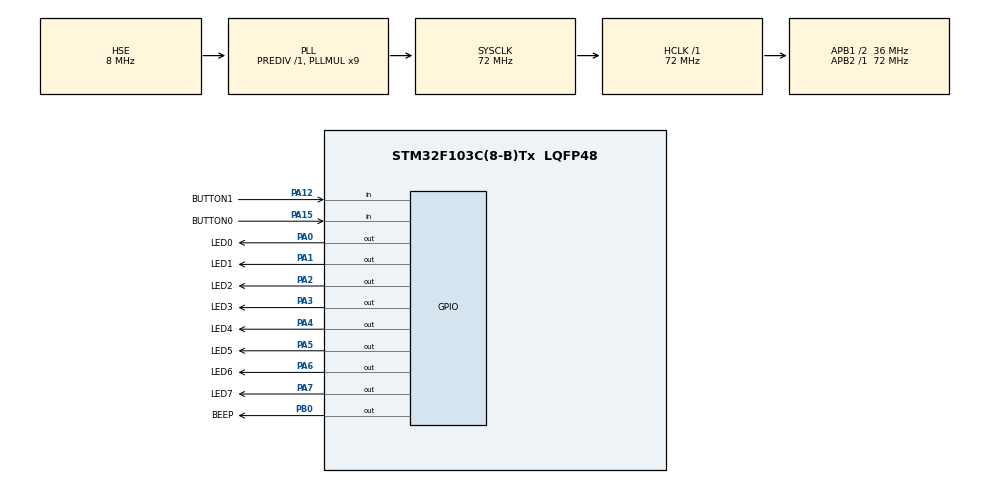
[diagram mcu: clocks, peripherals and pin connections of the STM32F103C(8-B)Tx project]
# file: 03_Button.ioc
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Mcu.Family=STM32F1
Mcu.Name=STM32F103C(8-B)Tx
Mcu.Package=LQFP48
NVIC.PriorityGroup=NVIC_PRIORITYGROUP_4
PA0-WKUP.GPIO_Label=LED0
PA0-WKUP.GPIO_ModeDefaultOutputPP=GPIO_MODE_OUTPUT_PP
PA0-WKUP.GPIO_PuPd=GPIO_PULLUP
PA0-WKUP.PinState=GPIO_PIN_SET
PA0-WKUP.Signal=GPIO_Output
PA1.GPIO_Label=LED1
PA1.GPIO_ModeDefaultOutputPP=GPIO_MODE_OUTPUT_PP
PA1.GPIO_PuPd=GPIO_PULLUP
PA1.GPIO_Speed=GPIO_SPEED_FREQ_LOW
PA1.PinState=GPIO_PIN_SET
PA1.Signal=GPIO_Output
PA12.GPIO_Label=BUTTON1
PA12.GPIO_PuPd=GPIO_PULLUP
PA12.Signal=GPIO_Input
PA13.Mode=Serial_Wire
PA13.Signal=SYS_JTMS-SWDIO
PA14.Mode=Serial_Wire
PA14.Signal=SYS_JTCK-SWCLK
PA15.GPIO_Label=BUTTON0
PA15.GPIO_PuPd=GPIO_PULLUP
PA15.Signal=GPIO_Input
PA2.GPIO_Label=LED2
PA2.GPIO_ModeDefaultOutputPP=GPIO_MODE_OUTPUT_PP
PA2.GPIO_PuPd=GPIO_PULLUP
PA2.GPIO_Speed=GPIO_SPEED_FREQ_LOW
PA2.PinState=GPIO_PIN_SET
PA2.Signal=GPIO_Output
PA3.GPIO_Label=LED3
PA3.GPIO_ModeDefaultOutputPP=GPIO_MODE_OUTPUT_PP
PA3.GPIO_PuPd=GPIO_PULLUP
PA3.GPIO_Speed=GPIO_SPEED_FREQ_LOW
PA3.PinState=GPIO_PIN_SET
PA3.Signal=GPIO_Output
PA4.GPIO_Label=LED4
PA4.GPIO_ModeDefaultOutputPP=GPIO_MODE_OUTPUT_PP
PA4.GPIO_PuPd=GPIO_PULLUP
PA4.GPIO_Speed=GPIO_SPEED_FREQ_LOW
PA4.PinState=GPIO_PIN_SET
PA4.Signal=GPIO_Output
PA5.GPIO_Label=LED5
PA5.GPIO_ModeDefaultOutputPP=GPIO_MODE_OUTPUT_PP
PA5.GPIO_PuPd=GPIO_PULLUP
PA5.GPIO_Speed=GPIO_SPEED_FREQ_LOW
PA5.PinState=GPIO_PIN_SET
PA5.Signal=GPIO_Output
PA6.GPIO_Label=LED6
PA6.GPIO_ModeDefaultOutputPP=GPIO_MODE_OUTPUT_PP
PA6.GPIO_PuPd=GPIO_PULLUP
PA6.GPIO_Speed=GPIO_SPEED_FREQ_LOW
PA6.PinState=GPIO_PIN_SET
PA6.Signal=GPIO_Output
PA7.GPIO_Label=LED7
PA7.GPIO_ModeDefaultOutputPP=GPIO_MODE_OUTPUT_PP
PA7.GPIO_PuPd=GPIO_PULLUP
PA7.GPIO_Speed=GPIO_SPEED_FREQ_LOW
PA7.PinState=GPIO_PIN_SET
PA7.Signal=GPIO_Output
PB0.GPIO_Label=BEEP
PB0.GPIO_PuPd=GPIO_PULLDOWN
PB0.Signal=GPIO_Output
PC14-OSC32_IN.Mode=LSE-External-Oscillator
PC14-OSC32_IN.Signal=RCC_OSC32_IN
PC15-OSC32_OUT.Mode=LSE-External-Oscillator
PC15-OSC32_OUT.Signal=RCC_OSC32_OUT
PD0-OSC_IN.Mode=HSE-External-Oscillator
PD0-OSC_IN.Signal=RCC_OSC_IN
PD1-OSC_OUT.Mode=HSE-External-Oscillator
PD1-OSC_OUT.Signal=RCC_OSC_OUT
ProjectManager.HeapSize=0x200
ProjectManager.StackSize=0x400
ProjectManager.TargetToolchain=STM32CubeIDE
RCC.AHBFreq_Value=72000000
RCC.APB1CLKDivider=RCC_HCLK_DIV2
RCC.APB1Freq_Value=36000000
RCC.APB1TimFreq_Value=72000000
RCC.APB2Freq_Value=72000000
RCC.APB2TimFreq_Value=72000000
RCC.HCLKFreq_Value=72000000
RCC.PLLMUL=RCC_PLL_MUL9
RCC.PLLSourceVirtual=RCC_PLLSOURCE_HSE
RCC.SYSCLKFreq_VALUE=72000000
RCC.SYSCLKSource=RCC_SYSCLKSOURCE_PLLCLK
RCC.USBFreq_Value=72000000
board=custom

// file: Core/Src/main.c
/* USER CODE BEGIN Header */
/**
  ******************************************************************************
  * @file           : main.c
  * @brief          : Main program body
  ******************************************************************************
  * @attention
  *
  * Copyright (c) 2025 STMicroelectronics.
  * All rights reserved.
  *
  * This software is licensed under terms that can be found in the LICENSE file
  * in the root directory of this software component.
  * If no LICENSE file comes with this software, it is provided AS-IS.
  *
  ******************************************************************************
  */
/* USER CODE END Header */
#include "main.h"
#include "gpio.h"

/* USER CODE BEGIN Includes */
#include "led.h"
#include "../../BSP/BEEP/beep.h"
#include "../../BSP/BUTTON/button.h"
/* USER CODE END Includes */

/* USER CODE BEGIN PD */
uint8_t button_down = 0;
/* USER CODE END PD */

void SystemClock_Config(void);

int main(void)
{

  /* MCU Configuration--------------------------------------------------------*/

  /* Reset of all peripherals, Initializes the Flash interface and the Systick. */
  HAL_Init();

  /* Configure the system clock */
  SystemClock_Config();

  /* Initialize all configured peripherals */
  MX_GPIO_Init();

  /* Infinite loop */
  while (1)
  {

    /* USER CODE BEGIN 3 */
	  button_down = button_scan(0);
	  if(button_down == BUTTON0_PRES)
		  HAL_GPIO_TogglePin(LED0_GPIO_Port, LED0_Pin);
	  HAL_Delay(10);
  }
  /* USER CODE END 3 */
}

void SystemClock_Config(void)
{
  RCC_OscInitTypeDef RCC_OscInitStruct = {0};
  RCC_ClkInitTypeDef RCC_ClkInitStruct = {0};

  /** Initializes the RCC Oscillators according to the specified parameters
  * in the RCC_OscInitTypeDef structure.
  */
  RCC_OscInitStruct.OscillatorType = RCC_OSCILLATORTYPE_HSE;
  RCC_OscInitStruct.HSEState = RCC_HSE_ON;
  RCC_OscInitStruct.HSEPredivValue = RCC_HSE_PREDIV_DIV1;
  RCC_OscInitStruct.HSIState = RCC_HSI_ON;
  RCC_OscInitStruct.PLL.PLLState = RCC_PLL_ON;
  RCC_OscInitStruct.PLL.PLLSource = RCC_PLLSOURCE_HSE;
  RCC_OscInitStruct.PLL.PLLMUL = RCC_PLL_MUL9;
  if (HAL_RCC_OscConfig(&RCC_OscInitStruct) != HAL_OK)
  {
    Error_Handler();
  }

  /** Initializes the CPU, AHB and APB buses clocks
  */
  RCC_ClkInitStruct.ClockType = RCC_CLOCKTYPE_HCLK|RCC_CLOCKTYPE_SYSCLK
                              |RCC_CLOCKTYPE_PCLK1|RCC_CLOCKTYPE_PCLK2;
  RCC_ClkInitStruct.SYSCLKSource = RCC_SYSCLKSOURCE_PLLCLK;
  RCC_ClkInitStruct.AHBCLKDivider = RCC_SYSCLK_DIV1;
  RCC_ClkInitStruct.APB1CLKDivider = RCC_HCLK_DIV2;
  RCC_ClkInitStruct.APB2CLKDivider = RCC_HCLK_DIV1;

  if (HAL_RCC_ClockConfig(&RCC_ClkInitStruct, FLASH_LATENCY_2) != HAL_OK)
  {
    Error_Handler();
  }
}

void Error_Handler(void)
{
  __disable_irq();
  while (1)
  {
  }
}
